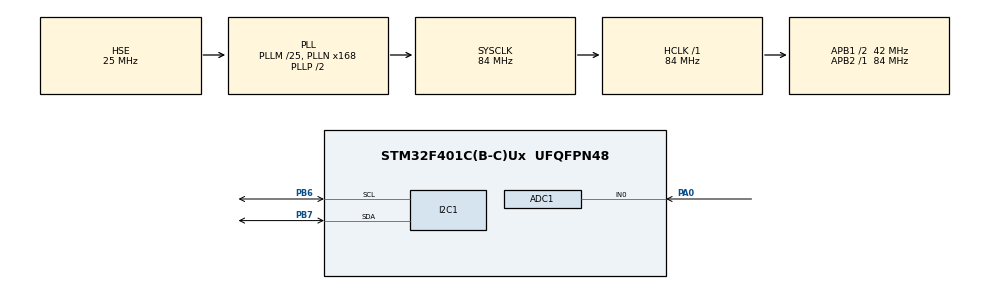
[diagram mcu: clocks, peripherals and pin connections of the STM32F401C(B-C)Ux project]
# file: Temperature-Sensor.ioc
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ADC1.Channel-0\#ChannelRegularConversion=ADC_CHANNEL_VREFINT
ADC1.Channel-1\#ChannelRegularConversion=ADC_CHANNEL_TEMPSENSOR
ADC1.ContinuousConvMode=ENABLE
ADC1.DMAContinuousRequests=ENABLE
ADC1.ExternalTrigConv=ADC_EXTERNALTRIGCONV_T3_TRGO
ADC1.NbrOfConversion=2
ADC1.NbrOfConversionFlag=1
ADC1.Rank-0\#ChannelRegularConversion=1
ADC1.Rank-1\#ChannelRegularConversion=2
ADC1.SamplingTime-0\#ChannelRegularConversion=ADC_SAMPLETIME_480CYCLES
ADC1.SamplingTime-1\#ChannelRegularConversion=ADC_SAMPLETIME_480CYCLES
ADC1.ScanConvMode=ENABLE
ADC1.master=1
Dma.ADC1.0.Direction=DMA_PERIPH_TO_MEMORY
Dma.ADC1.0.FIFOMode=DMA_FIFOMODE_DISABLE
Dma.ADC1.0.Instance=DMA2_Stream0
Dma.ADC1.0.MemDataAlignment=DMA_MDATAALIGN_HALFWORD
Dma.ADC1.0.MemInc=DMA_MINC_ENABLE
Dma.ADC1.0.Mode=DMA_CIRCULAR
Dma.ADC1.0.PeriphDataAlignment=DMA_PDATAALIGN_HALFWORD
Dma.ADC1.0.PeriphInc=DMA_PINC_DISABLE
Dma.ADC1.0.Priority=DMA_PRIORITY_LOW
Dma.Request0=ADC1
Mcu.Family=STM32F4
Mcu.Name=STM32F401C(B-C)Ux
Mcu.Package=UFQFPN48
NVIC.ADC_IRQn=true\:0\:0\:false\:false\:true\:true\:true\:true
NVIC.DMA2_Stream0_IRQn=true\:0\:0\:false\:false\:true\:false\:true\:true
NVIC.PriorityGroup=NVIC_PRIORITYGROUP_4
PA0-WKUP.Signal=ADCx_IN0
PA13.Mode=Serial_Wire
PA13.Signal=SYS_JTMS-SWDIO
PA14.Mode=Serial_Wire
PA14.Signal=SYS_JTCK-SWCLK
PB6.GPIO_Pu=GPIO_PULLUP
PB6.Mode=I2C
PB6.Signal=I2C1_SCL
PB7.GPIO_Pu=GPIO_PULLUP
PB7.Mode=I2C
PB7.Signal=I2C1_SDA
PH0\ -\ OSC_IN.Mode=HSE-External-Oscillator
PH0\ -\ OSC_IN.Signal=RCC_OSC_IN
PH1\ -\ OSC_OUT.Mode=HSE-External-Oscillator
PH1\ -\ OSC_OUT.Signal=RCC_OSC_OUT
ProjectManager.HeapSize=0x200
ProjectManager.StackSize=0x400
ProjectManager.TargetToolchain=STM32CubeIDE
RCC.48MHZClocksFreq_Value=42000000
RCC.AHBFreq_Value=84000000
RCC.APB1CLKDivider=RCC_HCLK_DIV2
RCC.APB1Freq_Value=42000000
RCC.APB1TimFreq_Value=84000000
RCC.APB2Freq_Value=84000000
RCC.APB2TimFreq_Value=84000000
RCC.CortexFreq_Value=84000000
RCC.HCLKFreq_Value=84000000
RCC.HSE_VALUE=25000000
RCC.HSI_VALUE=16000000
RCC.LSE_VALUE=32768
RCC.PLLM=25
RCC.PLLN=168
RCC.PLLSourceVirtual=RCC_PLLSOURCE_HSE
RCC.SYSCLKFreq_VALUE=84000000
RCC.SYSCLKSource=RCC_SYSCLKSOURCE_PLLCLK
RCC.VCOOutputFreq_Value=168000000
SH.ADCx_IN0.0=ADC1_IN0,IN0
TIM3.Period=10000-1
TIM3.TIM_MasterOutputTrigger=TIM_TRGO_UPDATE
VP_ADC1_TempSens_Input.Mode=IN-TempSens
VP_ADC1_Vref_Input.Mode=IN-Vrefint
VP_TIM3_VS_ClockSourceINT.Mode=Internal
board=custom

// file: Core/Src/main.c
/* USER CODE BEGIN Header */
/**
  ******************************************************************************
  * @file           : main.c
  * @brief          : Main program body
  ******************************************************************************
  * @attention
  *
  * Copyright (c) 2025 STMicroelectronics.
  * All rights reserved.
  *
  * This software is licensed under terms that can be found in the LICENSE file
  * in the root directory of this software component.
  * If no LICENSE file comes with this software, it is provided AS-IS.
  *
  ******************************************************************************
  */
/* USER CODE END Header */
#include "main.h"
#include "LCD.h"
#include "stdio.h"

ADC_HandleTypeDef hadc1;
DMA_HandleTypeDef hdma_adc1;

I2C_HandleTypeDef hi2c1;

TIM_HandleTypeDef htim3;

/* USER CODE BEGIN PV */

uint16_t AdcRaw[2];

uint8_t AdcConvCmplt = 0;

double Temperature;

char lcd_buffer[32];

/* USER CODE END PV */

void SystemClock_Config(void);
static void MX_GPIO_Init(void);
static void MX_DMA_Init(void);
static void MX_ADC1_Init(void);
static void MX_TIM3_Init(void);
static void MX_I2C1_Init(void);

int main(void)
{

  /* MCU Configuration--------------------------------------------------------*/

  /* Reset of all peripherals, Initializes the Flash interface and the Systick. */
  HAL_Init();

  /* Configure the system clock */
  SystemClock_Config();

  /* Initialize all configured peripherals */
  MX_GPIO_Init();
  MX_DMA_Init();
  MX_ADC1_Init();
  MX_TIM3_Init();
  MX_I2C1_Init();
  /* USER CODE BEGIN 2 */

  HAL_ADC_Start_DMA(&hadc1, (uint32_t*)AdcRaw, 2);
  HAL_TIM_Base_Start(&htim3);

  lcd_init(&hi2c1);
  lcd_clear();
  lcd_put_cur(0, 0);
  lcd_send_string("Temp Monitor");
  HAL_Delay(2000);

#define VREFINT 1.21 /* Internal reference voltage, V */
#define ADCMAX 4095.0 /* (2^12)-1 ADC maximum value */

#define V25 0.76 /* Sensors v at 25 c */
#define AVG_SLOPE 0.0025 /* 2.5 mV/ C */

  /* USER CODE END 2 */

  /* Infinite loop */
  /* USER CODE BEGIN WHILE */
  while (1)
  {
	//HAL_ADC_Start_DMA(&hadc1, (uint32_t*)AdcRaw, 2);
	//HAL_Delay(100);
	if(AdcConvCmplt){
		/* Something do */

		double VrefInt = (VREFINT*ADCMAX)/AdcRaw[0];

		double VTmpSens =  (VrefInt*AdcRaw[1])/ADCMAX;

		Temperature = (VTmpSens - V25)/(AVG_SLOPE) + 25.0;

		/* Display on LCD */
		lcd_clear();
		lcd_put_cur(0, 0);
		lcd_send_string("Temperature:");
		lcd_put_cur(1, 0);
		sprintf(lcd_buffer, "%.2f C", Temperature);
		lcd_send_string(lcd_buffer);

		AdcConvCmplt = 0;
	}
	HAL_Delay(1000);
    /* USER CODE END WHILE */

  }
}

void SystemClock_Config(void)
{
  RCC_OscInitTypeDef RCC_OscInitStruct = {0};
  RCC_ClkInitTypeDef RCC_ClkInitStruct = {0};

  /** Configure the main internal regulator output voltage
  */
  __HAL_RCC_PWR_CLK_ENABLE();
  __HAL_PWR_VOLTAGESCALING_CONFIG(PWR_REGULATOR_VOLTAGE_SCALE2);

  /** Initializes the RCC Oscillators according to the specified parameters
  * in the RCC_OscInitTypeDef structure.
  */
  RCC_OscInitStruct.OscillatorType = RCC_OSCILLATORTYPE_HSE;
  RCC_OscInitStruct.HSEState = RCC_HSE_ON;
  RCC_OscInitStruct.PLL.PLLState = RCC_PLL_ON;
  RCC_OscInitStruct.PLL.PLLSource = RCC_PLLSOURCE_HSE;
  RCC_OscInitStruct.PLL.PLLM = 25;
  RCC_OscInitStruct.PLL.PLLN = 168;
  RCC_OscInitStruct.PLL.PLLP = RCC_PLLP_DIV2;
  RCC_OscInitStruct.PLL.PLLQ = 4;
  if (HAL_RCC_OscConfig(&RCC_OscInitStruct) != HAL_OK)
  {
    Error_Handler();
  }

  /** Initializes the CPU, AHB and APB buses clocks
  */
  RCC_ClkInitStruct.ClockType = RCC_CLOCKTYPE_HCLK|RCC_CLOCKTYPE_SYSCLK
                              |RCC_CLOCKTYPE_PCLK1|RCC_CLOCKTYPE_PCLK2;
  RCC_ClkInitStruct.SYSCLKSource = RCC_SYSCLKSOURCE_PLLCLK;
  RCC_ClkInitStruct.AHBCLKDivider = RCC_SYSCLK_DIV1;
  RCC_ClkInitStruct.APB1CLKDivider = RCC_HCLK_DIV2;
  RCC_ClkInitStruct.APB2CLKDivider = RCC_HCLK_DIV1;

  if (HAL_RCC_ClockConfig(&RCC_ClkInitStruct, FLASH_LATENCY_2) != HAL_OK)
  {
    Error_Handler();
  }
}

static void MX_ADC1_Init(void)
{

  ADC_ChannelConfTypeDef sConfig = {0};

  /** Configure the global features of the ADC (Clock, Resolution, Data Alignment and number of conversion)
  */
  hadc1.Instance = ADC1;
  hadc1.Init.ClockPrescaler = ADC_CLOCK_SYNC_PCLK_DIV4;
  hadc1.Init.Resolution = ADC_RESOLUTION_12B;
  hadc1.Init.ScanConvMode = ENABLE;
  hadc1.Init.ContinuousConvMode = ENABLE;
  hadc1.Init.DiscontinuousConvMode = DISABLE;
  hadc1.Init.ExternalTrigConvEdge = ADC_EXTERNALTRIGCONVEDGE_RISING;
  hadc1.Init.ExternalTrigConv = ADC_EXTERNALTRIGCONV_T3_TRGO;
  hadc1.Init.DataAlign = ADC_DATAALIGN_RIGHT;
  hadc1.Init.NbrOfConversion = 2;
  hadc1.Init.DMAContinuousRequests = ENABLE;
  hadc1.Init.EOCSelection = ADC_EOC_SINGLE_CONV;
  if (HAL_ADC_Init(&hadc1) != HAL_OK)
  {
    Error_Handler();
  }

  /** Configure for the selected ADC regular channel its corresponding rank in the sequencer and its sample time.
  */
  sConfig.Channel = ADC_CHANNEL_VREFINT;
  sConfig.Rank = 1;
  sConfig.SamplingTime = ADC_SAMPLETIME_480CYCLES;
  if (HAL_ADC_ConfigChannel(&hadc1, &sConfig) != HAL_OK)
  {
    Error_Handler();
  }

  /** Configure for the selected ADC regular channel its corresponding rank in the sequencer and its sample time.
  */
  sConfig.Channel = ADC_CHANNEL_TEMPSENSOR;
  sConfig.Rank = 2;
  if (HAL_ADC_ConfigChannel(&hadc1, &sConfig) != HAL_OK)
  {
    Error_Handler();
  }

}

static void MX_I2C1_Init(void)
{

  hi2c1.Instance = I2C1;
  hi2c1.Init.ClockSpeed = 100000;
  hi2c1.Init.DutyCycle = I2C_DUTYCYCLE_2;
  hi2c1.Init.OwnAddress1 = 0;
  hi2c1.Init.AddressingMode = I2C_ADDRESSINGMODE_7BIT;
  hi2c1.Init.DualAddressMode = I2C_DUALADDRESS_DISABLE;
  hi2c1.Init.OwnAddress2 = 0;
  hi2c1.Init.GeneralCallMode = I2C_GENERALCALL_DISABLE;
  hi2c1.Init.NoStretchMode = I2C_NOSTRETCH_DISABLE;
  if (HAL_I2C_Init(&hi2c1) != HAL_OK)
  {
    Error_Handler();
  }

}

static void MX_TIM3_Init(void)
{

  TIM_ClockConfigTypeDef sClockSourceConfig = {0};
  TIM_MasterConfigTypeDef sMasterConfig = {0};

  htim3.Instance = TIM3;
  htim3.Init.Prescaler = 0;
  htim3.Init.CounterMode = TIM_COUNTERMODE_UP;
  htim3.Init.Period = 10000-1;
  htim3.Init.ClockDivision = TIM_CLOCKDIVISION_DIV1;
  htim3.Init.AutoReloadPreload = TIM_AUTORELOAD_PRELOAD_DISABLE;
  if (HAL_TIM_Base_Init(&htim3) != HAL_OK)
  {
    Error_Handler();
  }
  sClockSourceConfig.ClockSource = TIM_CLOCKSOURCE_INTERNAL;
  if (HAL_TIM_ConfigClockSource(&htim3, &sClockSourceConfig) != HAL_OK)
  {
    Error_Handler();
  }
  sMasterConfig.MasterOutputTrigger = TIM_TRGO_UPDATE;
  sMasterConfig.MasterSlaveMode = TIM_MASTERSLAVEMODE_DISABLE;
  if (HAL_TIMEx_MasterConfigSynchronization(&htim3, &sMasterConfig) != HAL_OK)
  {
    Error_Handler();
  }

}

static void MX_DMA_Init(void)
{

  /* DMA controller clock enable */
  __HAL_RCC_DMA2_CLK_ENABLE();

  /* DMA interrupt init */
  /* DMA2_Stream0_IRQn interrupt configuration */
  HAL_NVIC_SetPriority(DMA2_Stream0_IRQn, 0, 0);
  HAL_NVIC_EnableIRQ(DMA2_Stream0_IRQn);

}

static void MX_GPIO_Init(void)
{
	GPIO_InitTypeDef GPIO_InitStruct = {0};

  /* GPIO Ports Clock Enable */
  __HAL_RCC_GPIOH_CLK_ENABLE();
  __HAL_RCC_GPIOA_CLK_ENABLE();
  __HAL_RCC_GPIOB_CLK_ENABLE();

  /* USER CODE BEGIN MX_GPIO_Init_2 */
  GPIO_InitStruct.Pin = GPIO_PIN_6|GPIO_PIN_7;
  GPIO_InitStruct.Mode = GPIO_MODE_AF_OD;
  GPIO_InitStruct.Pull = GPIO_PULLUP;
  GPIO_InitStruct.Speed = GPIO_SPEED_FREQ_VERY_HIGH;
  GPIO_InitStruct.Alternate = GPIO_AF4_I2C1;
  HAL_GPIO_Init(GPIOB, &GPIO_InitStruct);
  /* USER CODE END MX_GPIO_Init_2 */
}

/* USER CODE BEGIN 4 */

void HAL_ADC_ConvCpltCallback(ADC_HandleTypeDef *hadc){
 if(hadc->Instance == ADC1){
	 AdcConvCmplt = 1;
 }

}
/* USER CODE END 4 */

void Error_Handler(void)
{
  __disable_irq();
  while (1)
  {
  }
}
